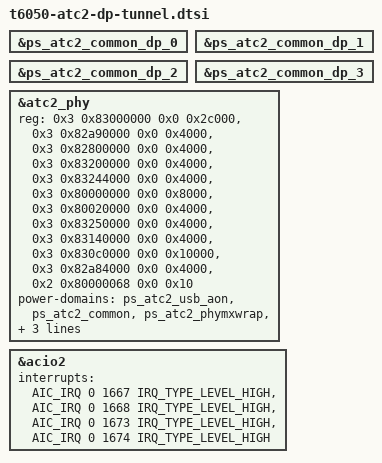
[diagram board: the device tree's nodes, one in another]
// SPDX-License-Identifier: GPL-2.0+ OR MIT
/*
 * The right port's (ATC2) USB4 DisplayPort tunnel clocks on T6050: the PHY's DP IN pixel clock
 * sources (dp-clock-source, one 32-bit source register per DP IN) and their four clock gates,
 * the PHY's dp0..dp3 power domains, and the router's DP IN interrupts (ADT atc2-dpin0..3).
 * Without the clock sources the DCP fabric gets -EOPNOTSUPP for every tunnel link rate, and a
 * display behind a USB4/Thunderbolt dock or enclosure on this port stays dark.
 * Addresses and interrupts are the T6050's (J714sAP and K114sAP ADT agree). Shared by the boards
 * that describe the ATC2 router: J714s (t6050-j714s-display.dtsi), K114s and K114c
 * (t6050-k114-usb.dtsi).
 */

&ps_atc2_common_dp_0 {
	status = "okay";
};

&ps_atc2_common_dp_1 {
	status = "okay";
};

&ps_atc2_common_dp_2 {
	status = "okay";
};

&ps_atc2_common_dp_3 {
	status = "okay";
};

&atc2_phy {
	reg = <0x3 0x83000000 0x0 0x2c000>,
	      <0x3 0x82a90000 0x0 0x4000>,
	      <0x3 0x82800000 0x0 0x4000>,
	      <0x3 0x83200000 0x0 0x4000>,
	      <0x3 0x83244000 0x0 0x4000>,
	      <0x3 0x80000000 0x0 0x8000>,
	      <0x3 0x80020000 0x0 0x4000>,
	      <0x3 0x83250000 0x0 0x4000>,
	      <0x3 0x83140000 0x0 0x4000>,
	      <0x3 0x830c0000 0x0 0x10000>,
	      <0x3 0x82a84000 0x0 0x4000>,
	      <0x2 0x80000068 0x0 0x10>;
	reg-names = "core", "usb2phy", "usb2-digital", "reset", "fabric", "axi2af", "lioa",
		    "common-cfg", "usb-control", "firmware-data", "pipehandler",
		    "dp-clock-source";
	power-domains = <&ps_atc2_usb_aon>, <&ps_atc2_common>, <&ps_atc2_phymxwrap>,
			<&ps_atc2_usb>, <&ps_atc2_common_dp_0>, <&ps_atc2_common_dp_1>,
			<&ps_atc2_common_dp_2>, <&ps_atc2_common_dp_3>;
	power-domain-names = "usb-aon", "common", "wrapper", "usb", "dp0", "dp1", "dp2", "dp3";
};

/* The right router's DP IN interrupts (ADT atc2-dpin0..3) */
&acio2 {
	interrupts = <AIC_IRQ 0 1667 IRQ_TYPE_LEVEL_HIGH>, <AIC_IRQ 0 1668 IRQ_TYPE_LEVEL_HIGH>,
		     <AIC_IRQ 0 1673 IRQ_TYPE_LEVEL_HIGH>, <AIC_IRQ 0 1674 IRQ_TYPE_LEVEL_HIGH>;
	interrupt-names = "dpin0", "dpin1", "dpin2", "dpin3";
};
